VERSION ""

NS_ :

BS_:

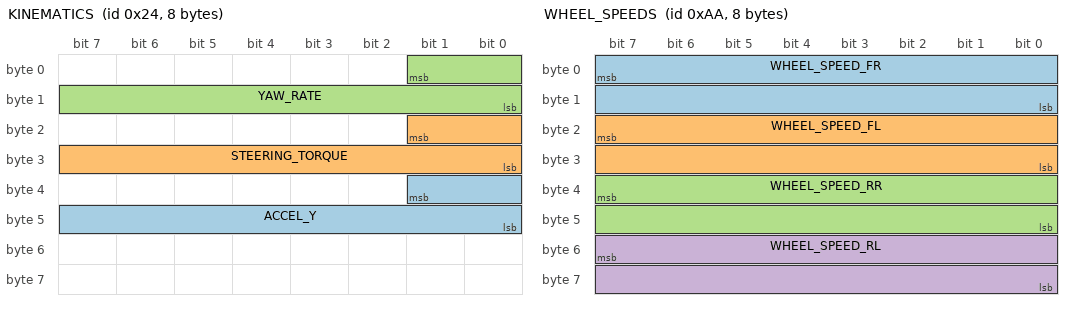
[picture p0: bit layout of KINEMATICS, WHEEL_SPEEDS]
BO_ 36 KINEMATICS: 8 XXX
 SG_ ACCEL_Y : 33|10@0+ (1,-512) [0|65535] "" XXX
 SG_ STEERING_TORQUE : 17|10@0+ (1,-512) [0|65535] "" XXX
 SG_ YAW_RATE : 1|10@0+ (1,-512) [0|65535] "" XXX

BO_ 166 BRAKE: 8 XXX
 SG_ BRAKE_AMOUNT : 7|8@0+ (1,0) [0|255] "" XXX
 SG_ BRAKE_PEDAL : 23|8@0+ (1,0) [0|255] "" XXX

BO_ 170 WHEEL_SPEEDS: 8 XXX
 SG_ WHEEL_SPEED_FR : 7|16@0+ (0.0062,-67.67) [0|250] "mph" XXX
 SG_ WHEEL_SPEED_FL : 23|16@0+ (0.0062,-67.67) [0|250] "mph" XXX
 SG_ WHEEL_SPEED_RR : 39|16@0+ (0.0062,-67.67) [0|250] "mph" XXX
 SG_ WHEEL_SPEED_RL : 55|16@0+ (0.0062,-67.67) [0|250] "mph" XXX

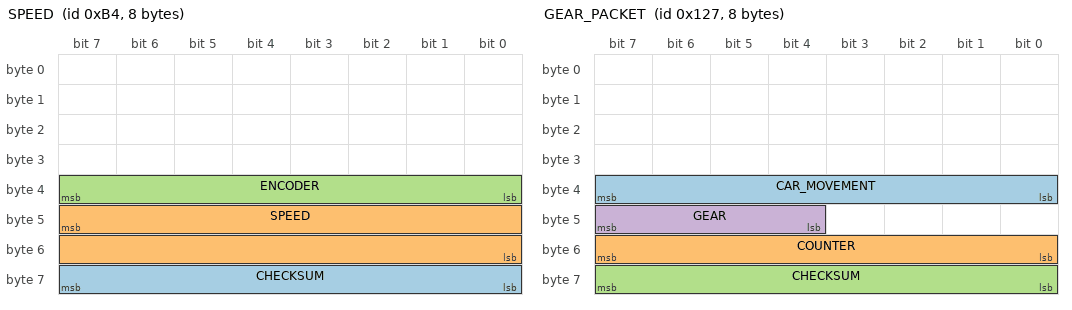
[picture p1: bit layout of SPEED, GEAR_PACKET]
BO_ 180 SPEED: 8 XXX
 SG_ CHECKSUM : 63|8@0+ (1,0) [0|255] "" XXX
 SG_ SPEED : 47|16@0+ (0.0062,0) [0|115] "mph" XXX
 SG_ ENCODER : 39|8@0+ (1,0) [0|255] "" XXX

BO_ 295 GEAR_PACKET: 8 XXX
 SG_ CAR_MOVEMENT : 39|8@0- (1,0) [0|255] "" XXX
 SG_ COUNTER : 55|8@0+ (1,0) [0|255] "" XXX
 SG_ CHECKSUM : 63|8@0+ (1,0) [0|255] "" XXX
 SG_ GEAR : 47|4@0+ (1,0) [0|15] "" XXX

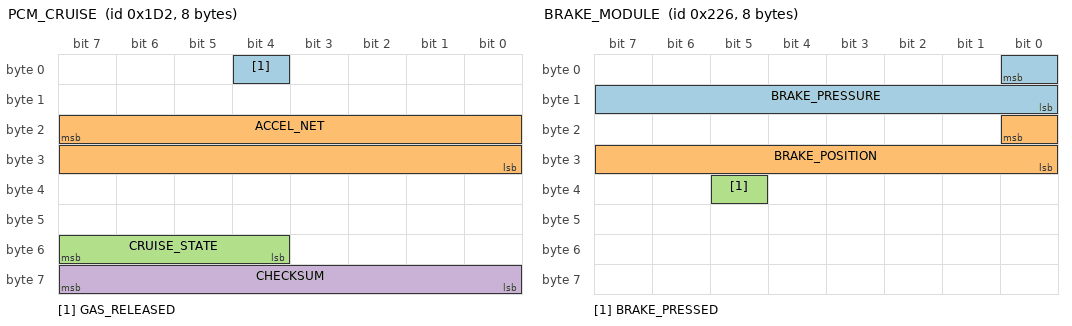
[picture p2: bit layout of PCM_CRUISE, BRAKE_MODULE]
BO_ 466 PCM_CRUISE: 8 XXX
 SG_ GAS_RELEASED : 4|1@0+ (1,0) [0|1] "" XXX
 SG_ ACCEL_NET : 23|16@0- (0.001,0) [-20|20] "m/s2" XXX
 SG_ CRUISE_STATE : 55|4@0+ (1,0) [0|15] "" XXX
 SG_ CHECKSUM : 63|8@0+ (1,0) [0|255] "" XXX

BO_ 550 BRAKE_MODULE: 8 XXX
 SG_ BRAKE_PRESSURE : 0|9@0+ (1,0) [0|511] "" XXX
 SG_ BRAKE_POSITION : 16|9@0+ (1,0) [0|511] "" XXX
 SG_ BRAKE_PRESSED : 37|1@0+ (1,0) [0|1] "" XXX

BO_ 552 ACCELEROMETER: 8 XXX
 SG_ ACCEL_Z : 22|15@0- (1,0) [0|32767] "" XXX
 SG_ ACCEL_X : 6|15@0- (0.001,0) [-20|20] "m/s2" XXX

BO_ 560 BRAKE_MODULE2: 8 XXX
 SG_ BRAKE_LIGHTS : 26|1@0+ (1,0) [0|1] "" XXX

BO_ 581 GAS_PEDAL: 8 XXX
 SG_ GAS_PEDAL : 23|8@0+ (0.005,0) [0|1] "" XXX

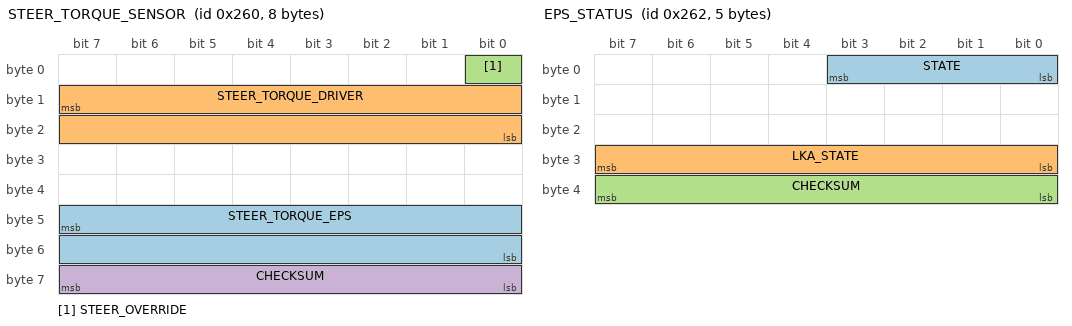
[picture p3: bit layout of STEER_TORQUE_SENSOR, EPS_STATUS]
BO_ 608 STEER_TORQUE_SENSOR: 8 XXX
 SG_ STEER_TORQUE_EPS : 47|16@0- (0.66,0) [-20000|20000] "" XXX
 SG_ STEER_TORQUE_DRIVER : 15|16@0- (1,0) [-32768|32767] "" XXX
 SG_ STEER_OVERRIDE : 0|1@0+ (1,0) [0|1] "" XXX
 SG_ CHECKSUM : 63|8@0+ (1,0) [0|255] "" XXX

BO_ 610 EPS_STATUS: 5 EPS
 SG_ STATE : 3|4@0+ (1,0) [0|15] "" XXX
 SG_ LKA_STATE : 31|8@0+ (1,0) [0|255] "" XXX
 SG_ CHECKSUM : 39|8@0+ (1,0) [0|255] "" XXX

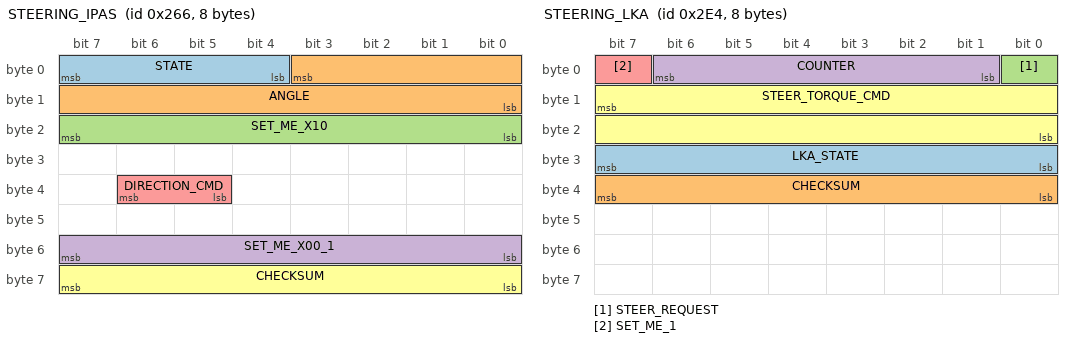
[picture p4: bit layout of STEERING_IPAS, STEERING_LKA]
BO_ 614 STEERING_IPAS: 8 IPAS
 SG_ STATE : 7|4@0+ (1,0) [0|15] "" XXX
 SG_ ANGLE : 3|12@0- (1,0) [0|16777215] "" XXX
 SG_ SET_ME_X10 : 23|8@0+ (1,0) [0|255] "" XXX
 SG_ SET_ME_X00_1 : 55|8@0+ (1,0) [0|255] "" XXX
 SG_ DIRECTION_CMD : 38|2@0+ (1,0) [0|3] "" XXX
 SG_ CHECKSUM : 63|8@0+ (1,0) [0|255] "" XXX

BO_ 643 PRE_COLLISION: 8 XXX

BO_ 740 STEERING_LKA: 8 XXX
 SG_ LKA_STATE : 31|8@0+ (1,0) [0|255] "" XXX
 SG_ CHECKSUM : 39|8@0+ (1,0) [0|255] "" XXX
 SG_ STEER_REQUEST : 0|1@0+ (1,0) [0|1] "" XXX
 SG_ COUNTER : 6|6@0+ (1,0) [0|63] "" XXX
 SG_ SET_ME_1 : 7|1@0+ (1,0) [0|1] "" XXX
 SG_ STEER_TORQUE_CMD : 15|16@0- (1,0) [0|65535] "" XXX

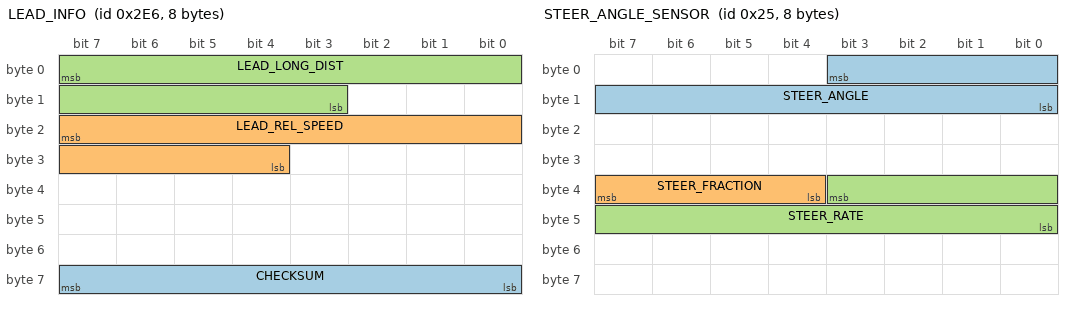
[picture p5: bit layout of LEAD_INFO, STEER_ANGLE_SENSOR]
BO_ 742 LEAD_INFO: 8 DSU
 SG_ CHECKSUM : 63|8@0+ (1,0) [0|255] "" HCU
 SG_ LEAD_REL_SPEED : 23|12@0- (0.025,0) [-100|100] "m/s" HCU
 SG_ LEAD_LONG_DIST : 7|13@0+ (0.05,0) [0|300] "m" HCU

BO_ 835 ACC_CONTROL: 8 DSU
 SG_ ACCEL_CMD : 7|16@0- (0.001,0) [-20|20] "m/s2" HCU

BO_ 1556 STEERING_LEVERS: 8 XXX
 SG_ TURN_SIGNALS : 29|2@0+ (1,0) [0|3] "" XXX

BO_ 37 STEER_ANGLE_SENSOR: 8 XXX
 SG_ STEER_ANGLE : 3|12@0- (1.5,0) [-500|500] "deg" XXX
 SG_ STEER_FRACTION : 39|4@0- (0.1,0) [-0.7|0.7] "deg" XXX
 SG_ STEER_RATE : 35|12@0- (1,0) [-2000|2000] "deg/s" XXX

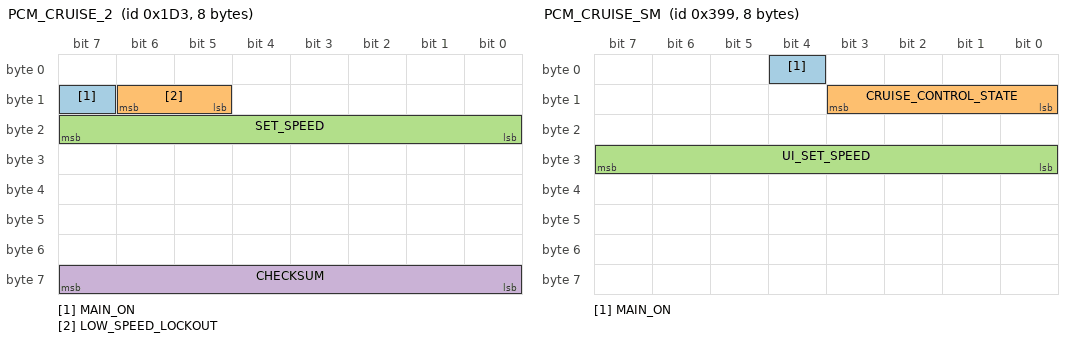
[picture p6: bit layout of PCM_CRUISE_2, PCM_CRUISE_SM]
BO_ 467 PCM_CRUISE_2: 8 XXX
 SG_ MAIN_ON : 15|1@0+ (1,0) [0|1] "" XXX
 SG_ LOW_SPEED_LOCKOUT : 14|2@0+ (1,0) [0|3] "kph" XXX
 SG_ SET_SPEED : 23|8@0+ (1,0) [0|255] "kph" XXX
 SG_ CHECKSUM : 63|8@0+ (1,0) [0|255] "" XXX

BO_ 921 PCM_CRUISE_SM: 8 XXX
 SG_ MAIN_ON : 4|1@0+ (1,0) [0|1] "" XXX
 SG_ CRUISE_CONTROL_STATE : 11|4@0+ (1,0) [0|15] "" XXX
 SG_ UI_SET_SPEED : 31|8@0+ (1,0) [0|255] "" XXX

BO_ 951 ESP_CONTROL: 8 ESP
 SG_ TC_DISABLED : 13|1@0+ (1,0) [0|1] "" XXX

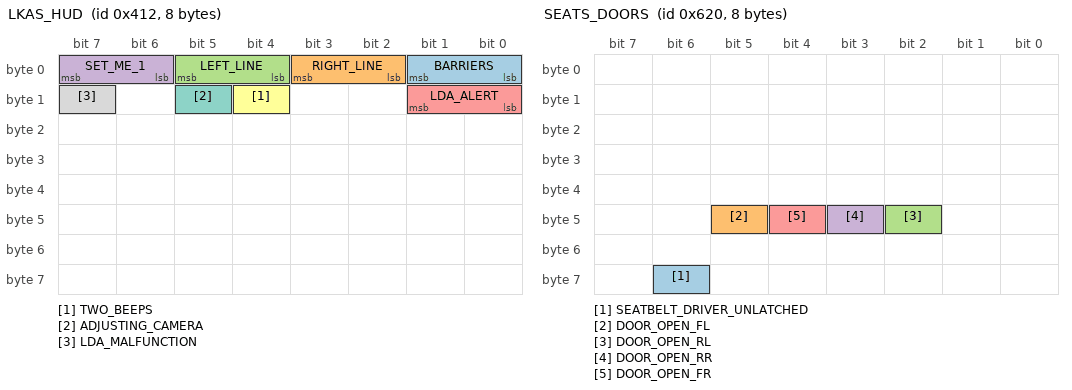
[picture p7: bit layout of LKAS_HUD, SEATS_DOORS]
BO_ 1042 LKAS_HUD: 8 XXX
 SG_ BARRIERS : 1|2@0+ (1,0) [0|3] "" XXX
 SG_ RIGHT_LINE : 3|2@0+ (1,0) [0|3] "" XXX
 SG_ LEFT_LINE : 5|2@0+ (1,0) [0|3] "" XXX
 SG_ SET_ME_1 : 7|2@0+ (1,0) [0|3] "" XXX
 SG_ LDA_ALERT : 9|2@0+ (1,0) [0|3] "" XXX
 SG_ TWO_BEEPS : 12|1@0+ (1,0) [0|1] "" XXX
 SG_ ADJUSTING_CAMERA : 13|1@0+ (1,0) [0|1] "" XXX
 SG_ LDA_MALFUNCTION : 15|1@0+ (1,0) [0|1] "" XXX

BO_ 1553 UI_SEETING: 8 XXX
 SG_ UNITS : 26|2@0+ (1,0) [0|3] "" XXX

BO_ 1568 SEATS_DOORS: 8 XXX
 SG_ SEATBELT_DRIVER_UNLATCHED : 62|1@0+ (1,0) [0|1] "" XXX
 SG_ DOOR_OPEN_FL : 45|1@0+ (1,0) [0|1] "" XXX
 SG_ DOOR_OPEN_RL : 42|1@0+ (1,0) [0|1] "" XXX
 SG_ DOOR_OPEN_RR : 43|1@0+ (1,0) [0|1] "" XXX
 SG_ DOOR_OPEN_FR : 44|1@0+ (1,0) [0|1] "" XXX

BO_ 452 POWERTRAIN: 8 XXX
 SG_ ENGINE_RPM : 7|16@0+ (1,0) [0|65535] "rpm" XXX
 SG_ CHECKSUM : 63|8@0+ (1,0) [0|255] "" XXX

BU_: XXX

VAL_ 53 GEAR 0 "P" 5 "D" 6 "N" 7 "R" ;
VAL_ 64 GEAR 0 "P" 5 "D" 6 "N" 7 "R" ;
VAL_ 69 GEAR 0 "P" 5 "D" 6 "N" 7 "R" ;
VAL_ 112 GEAR 0 "P" 5 "D" 6 "N" 7 "R" ;
VAL_ 80 LKA_ICON 0 "hidden" 1 "grey" 2 "green" 3 "flashing green" ;
VAL_ 80 LKA_MODE 1 "warning only" 2 "assist" 6 "off" ;
VAL_ 96 TRACTION_AND_STABILITY_CONTROL 0 "On" 5 "Limited" 1 "Off";
VAL_ 234 LKA_FAULT 0 "ok" 1 "lka fault" ;
VAL_ 272 LKA_ICON 0 "hidden" 1 "grey" 2 "green" 3 "flashing green" ;
VAL_ 272 LKA_MODE 1 "warning only" 2 "assist" 6 "off" ;
VAL_ 298 LKA_ICON 0 "hidden" 1 "grey" 2 "green" 3 "flashing green" ;
VAL_ 298 LKA_MODE 1 "warning only" 2 "assist" 6 "off" ;
VAL_ 304 PARK_BUTTON 1 "Pressed" 2 "Not Pressed";
VAL_ 304 KNOB_POSITION 1 "R" 2 "N (on R side)" 3 "Centered" 4 "N (on D side)" 5 "D";
VAL_ 304 GEAR 1 "P" 2 "R" 3 "N" 4 "D" ;
VAL_ 352 AEB_SETTING 1 "off" 2 "warning only" 3 "active assist" ;
VAL_ 362 BLINKER_CONTROL 1 "hazards" 2 "hazards button backlight" 3 "left blinkers" 4 "right blinkers";
VAL_ 373 ACCEnable 0 "SCC ready" 1 "SCC temp fault" 2 "SCC permanent fault" 3 "SCC permanent fault, communication issue";
VAL_ 416 ACCMode 0 "off" 1 "enabled" 2 "driver_override" 3 "off_maybe_fault" 4 "cancelled" ;
VAL_ 426 CRUISE_BUTTONS 0 "none" 1 "res_accel" 2 "set_decel" 3 "gap_distance" 4 "pause_resume" ;
VAL_ 463 CRUISE_BUTTONS 0 "none" 1 "res_accel" 2 "set_decel" 3 "gap_distance" 4 "pause_resume" ;
VAL_ 463 RIGHT_PADDLE 0 "Not Pulled" 1 "Pulled";
VAL_ 463 LEFT_PADDLE 0 "Not Pulled" 1 "Pulled";
VAL_ 676 LEFT_LANE_LINE 0 "Not Detected" 1 "Low Confidence" 2 "Medium Confidence" 3 "High Confidence";
VAL_ 676 RIGHT_LANE_LINE 0 "Not Detected" 1 "Low Confidence" 2 "Medium Confidence" 3 "High Confidence";
VAL_ 736 MSLA_STATUS 0 "disabled" 1 "active" 2 "paused";
VAL_ 866 LEFT_LANE_LINE 0 "Not Detected" 1 "Low Confidence" 2 "Medium Confidence" 3 "High Confidence";
VAL_ 866 RIGHT_LANE_LINE 0 "Not Detected" 1 "Low Confidence" 2 "Medium Confidence" 3 "High Confidence";
VAL_ 1041 DRIVER_DOOR 0 "Closed" 1 "Opened";
VAL_ 1041 PASSENGER_DOOR 0 "Closed" 1 "Opened";
VAL_ 1041 DRIVER_REAR_DOOR 0 "Closed" 1 "Opened";
VAL_ 1041 PASSENGER_REAR_DOOR 0 "Closed" 1 "Opened";
VAL_ 1041 DRIVER_SEATBELT 0 "Unlatched" 1 "Latched";
VAL_ 1041 PASSENGER_SEATBELT 0 "Unlatched" 1 "Latched";
VAL_ 1144 DRIVE_MODE2 3 "Set Sport" 1 "Set Normal" 2 "Set Eco";
